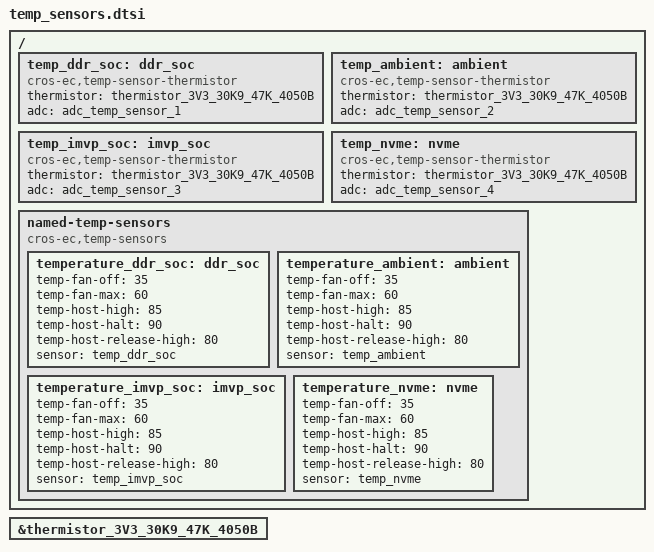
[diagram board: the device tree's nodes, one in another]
/* Copyright 2024 The ChromiumOS Authors
 * Use of this source code is governed by a BSD-style license that can be
 * found in the LICENSE file.
 */

#include <cros/thermistor/thermistor.dtsi>

/ {
	temp_ddr_soc: ddr_soc {
		compatible = "cros-ec,temp-sensor-thermistor";
		thermistor = <&thermistor_3V3_30K9_47K_4050B>;
		adc = <&adc_temp_sensor_1>;
	};
	temp_ambient: ambient {
		compatible = "cros-ec,temp-sensor-thermistor";
		thermistor = <&thermistor_3V3_30K9_47K_4050B>;
		adc = <&adc_temp_sensor_2>;
	};
	temp_imvp_soc: imvp_soc {
		compatible = "cros-ec,temp-sensor-thermistor";
		thermistor = <&thermistor_3V3_30K9_47K_4050B>;
		adc = <&adc_temp_sensor_3>;
	};
	temp_nvme: nvme {
		compatible = "cros-ec,temp-sensor-thermistor";
		thermistor = <&thermistor_3V3_30K9_47K_4050B>;
		adc = <&adc_temp_sensor_4>;
	};

	named-temp-sensors {
		compatible = "cros-ec,temp-sensors";
		temperature_ddr_soc: ddr_soc {
			temp-fan-off = <35>;
			temp-fan-max = <60>;
			temp-host-high = <85>;
			temp-host-halt = <90>;
			temp-host-release-high = <80>;
			sensor = <&temp_ddr_soc>;
		};
		temperature_ambient: ambient {
			temp-fan-off = <35>;
			temp-fan-max = <60>;
			temp-host-high = <85>;
			temp-host-halt = <90>;
			temp-host-release-high = <80>;
			sensor = <&temp_ambient>;
		};
		temperature_imvp_soc: imvp_soc {
			temp-fan-off = <35>;
			temp-fan-max = <60>;
			temp-host-high = <85>;
			temp-host-halt = <90>;
			temp-host-release-high = <80>;
			sensor = <&temp_imvp_soc>;
		};
		temperature_nvme: nvme {
			temp-fan-off = <35>;
			temp-fan-max = <60>;
			temp-host-high = <85>;
			temp-host-halt = <90>;
			temp-host-release-high = <80>;
			sensor = <&temp_nvme>;
		};
	};
};

&thermistor_3V3_30K9_47K_4050B {
	status = "okay";
};
